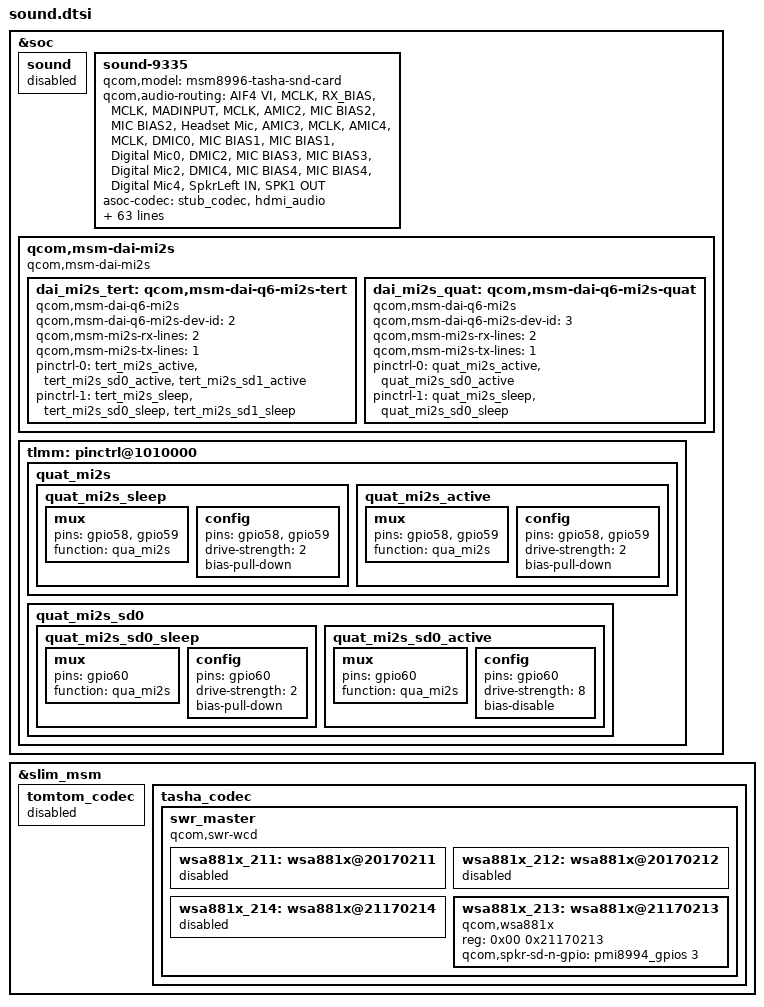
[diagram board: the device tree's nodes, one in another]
/* Copyright (c) 2015, The Linux Foundation. All rights reserved.
 *
 * This program is free software; you can redistribute it and/or modify
 * it under the terms of the GNU General Public License version 2 and
 * only version 2 as published by the Free Software Foundation.
 *
 * This program is distributed in the hope that it will be useful,
 * but WITHOUT ANY WARRANTY; without even the implied warranty of
 * MERCHANTABILITY or FITNESS FOR A PARTICULAR PURPOSE.  See the
 * GNU General Public License for more details.
 */


&soc {

	sound {
		status = "disabled";
	};

	sound-9335 {
		qcom,model = "msm8996-tasha-snd-card";

		qcom,audio-routing =
			"AIF4 VI", "MCLK",
			"RX_BIAS", "MCLK",
			"MADINPUT", "MCLK",
			"AMIC2", "MIC BIAS2",
			"MIC BIAS2", "Headset Mic",
			"AMIC3", "MCLK",
			"AMIC4", "MCLK",
			"DMIC0", "MIC BIAS1",
			"MIC BIAS1", "Digital Mic0",
			"DMIC2", "MIC BIAS3",
			"MIC BIAS3", "Digital Mic2",
			"DMIC4", "MIC BIAS4",
			"MIC BIAS4", "Digital Mic4",
			"SpkrLeft IN", "SPK1 OUT";

		asoc-codec = <&stub_codec>, <&hdmi_audio>;
		asoc-codec-names = "msm-stub-codec.1", "msm-hdmi-audio-codec-rx";
		asoc-cpu = <&dai_pri_auxpcm>, <&dai_sec_auxpcm>, <&dai_hdmi>, <&dai_mi2s_sec>, <&dai_mi2s_tert>,<&dai_mi2s_quat>,
			<&sb_0_rx>, <&sb_0_tx>, <&sb_1_rx>, <&sb_1_tx>,
			<&sb_2_rx>, <&sb_2_tx>, <&sb_3_rx>, <&sb_3_tx>,
			<&sb_4_rx>, <&sb_4_tx>, <&sb_5_tx>, <&afe_pcm_rx>,
			<&afe_pcm_tx>, <&afe_proxy_rx>, <&afe_proxy_tx>,
			<&incall_record_rx>, <&incall_record_tx>,
			<&incall_music_rx>, <&incall_music2_rx>,
			<&sb_5_rx>, <&sb_6_rx>,
			<&usb_audio_rx>, <&usb_audio_tx>,
			<&dai_pri_tdm_tx_0>, <&dai_pri_tdm_tx_1>,
			<&dai_pri_tdm_tx_2>, <&dai_pri_tdm_tx_3>,
			<&dai_pri_tdm_rx_0>, <&dai_pri_tdm_rx_1>,
			<&dai_pri_tdm_rx_2>, <&dai_pri_tdm_rx_3>,
			<&dai_sec_tdm_rx_0>, <&dai_sec_tdm_rx_1>,
			<&dai_sec_tdm_rx_2>, <&dai_sec_tdm_rx_3>,
			<&dai_sec_tdm_tx_0>, <&dai_sec_tdm_tx_1>,
			<&dai_sec_tdm_tx_2>, <&dai_sec_tdm_tx_3>,
			<&dai_tert_tdm_rx_0>, <&dai_tert_tdm_rx_1>,
			<&dai_tert_tdm_rx_2>, <&dai_tert_tdm_rx_3>,
			<&dai_tert_tdm_tx_0>, <&dai_tert_tdm_tx_1>,
			<&dai_tert_tdm_tx_2>, <&dai_tert_tdm_tx_3>,
			<&dai_quat_tdm_rx_0>, <&dai_quat_tdm_rx_1>,
			<&dai_quat_tdm_rx_2>, <&dai_quat_tdm_rx_3>,
			<&dai_quat_tdm_tx_0>, <&dai_quat_tdm_tx_1>,
			<&dai_quat_tdm_tx_2>, <&dai_quat_tdm_tx_3>;
		asoc-cpu-names = "msm-dai-q6-auxpcm.1", "msm-dai-q6-auxpcm.2",
			"msm-dai-q6-hdmi.8", "msm-dai-q6-mi2s.1","msm-dai-q6-mi2s.2","msm-dai-q6-mi2s.3",
			"msm-dai-q6-dev.16384", "msm-dai-q6-dev.16385",
			"msm-dai-q6-dev.16386", "msm-dai-q6-dev.16387",
			"msm-dai-q6-dev.16388", "msm-dai-q6-dev.16389",
			"msm-dai-q6-dev.16390", "msm-dai-q6-dev.16391",
			"msm-dai-q6-dev.16392", "msm-dai-q6-dev.16393",
			"msm-dai-q6-dev.16395",
			"msm-dai-q6-dev.224", "msm-dai-q6-dev.225",
			"msm-dai-q6-dev.241", "msm-dai-q6-dev.240",
			"msm-dai-q6-dev.32771", "msm-dai-q6-dev.32772",
			"msm-dai-q6-dev.32773", "msm-dai-q6-dev.32770",
			"msm-dai-q6-dev.16394", "msm-dai-q6-dev.16396",
			"msm-dai-q6-dev.28672", "msm-dai-q6-dev.28673",
			"msm-dai-q6-tdm.36865", "msm-dai-q6-tdm.36867",
			"msm-dai-q6-tdm.36869", "msm-dai-q6-tdm.36871",
			"msm-dai-q6-tdm.36864", "msm-dai-q6-tdm.36866",
			"msm-dai-q6-tdm.36868", "msm-dai-q6-tdm.36870",
			"msm-dai-q6-tdm.36880", "msm-dai-q6-tdm.36882",
			"msm-dai-q6-tdm.36884", "msm-dai-q6-tdm.36886",
			"msm-dai-q6-tdm.36881", "msm-dai-q6-tdm.36883",
			"msm-dai-q6-tdm.36885", "msm-dai-q6-tdm.36887",
			"msm-dai-q6-tdm.36896", "msm-dai-q6-tdm.36898",
			"msm-dai-q6-tdm.36900", "msm-dai-q6-tdm.36902",
			"msm-dai-q6-tdm.36897", "msm-dai-q6-tdm.36899",
			"msm-dai-q6-tdm.36901", "msm-dai-q6-tdm.36903",
			"msm-dai-q6-tdm.36912", "msm-dai-q6-tdm.36914",
			"msm-dai-q6-tdm.36916", "msm-dai-q6-tdm.36918",
			"msm-dai-q6-tdm.36913", "msm-dai-q6-tdm.36915",
			"msm-dai-q6-tdm.36917", "msm-dai-q6-tdm.36919";
		qcom,wsa-max-devs = <1>;
		qcom,wsa-devs = <&wsa881x_213>;
		qcom,wsa-aux-dev-prefix = "SpkrLeft";
		qcom,msm-mbhc-hphl-swh = <1>;
		qcom,mbhc-audio-jack-type = "4-pole-jack";
	};

	qcom,msm-dai-mi2s {
		compatible = "qcom,msm-dai-mi2s";
		dai_mi2s_tert: qcom,msm-dai-q6-mi2s-tert {
			compatible = "qcom,msm-dai-q6-mi2s";
			qcom,msm-dai-q6-mi2s-dev-id = <2>;
			qcom,msm-mi2s-rx-lines = <2>;
			qcom,msm-mi2s-tx-lines = <1>;
			pinctrl-names = "default", "idle";
			pinctrl-0 = <&tert_mi2s_active &tert_mi2s_sd0_active &tert_mi2s_sd1_active>;
			pinctrl-1 = <&tert_mi2s_sleep &tert_mi2s_sd0_sleep &tert_mi2s_sd1_sleep>;
		};

        dai_mi2s_quat: qcom,msm-dai-q6-mi2s-quat {
			compatible = "qcom,msm-dai-q6-mi2s";
			qcom,msm-dai-q6-mi2s-dev-id = <3>;
			qcom,msm-mi2s-rx-lines = <2>; /* SD0 (1 << 0) | SD1 (1 << 1) | SD2 (1 << 2) */
			qcom,msm-mi2s-tx-lines = <1>; /* SD2 (1 << 3) */
			pinctrl-names = "default", "sleep";
			pinctrl-0 = <&quat_mi2s_active &quat_mi2s_sd0_active>;
			pinctrl-1 = <&quat_mi2s_sleep &quat_mi2s_sd0_sleep>;
		};
	};

	tlmm: pinctrl@1010000 {
			quat_mi2s {
				quat_mi2s_sleep: quat_mi2s_sleep {
					mux {
						pins = "gpio58", "gpio59";
						function = "qua_mi2s";
					};

					config {
						pins = "gpio58", "gpio59";
						drive-strength = <2>;   /* 2 mA */
						bias-pull-down;         /* PULL DOWN */
					};
				};
				quat_mi2s_active: quat_mi2s_active {
					mux {
						pins = "gpio58", "gpio59";
						function = "qua_mi2s";
					};

					config {
						pins = "gpio58", "gpio59";
						drive-strength = <2>;
						bias-pull-down;
					};
				};
			};

			quat_mi2s_sd0 {
				quat_mi2s_sd0_sleep: quat_mi2s_sd0_sleep {
					mux {
						pins = "gpio60";
						function = "qua_mi2s";
					};

					config {
						pins = "gpio60";
						drive-strength = <2>;   /* 2 mA */
						bias-pull-down;         /* PULL DOWN */
					};
				};
				quat_mi2s_sd0_active: quat_mi2s_sd0_active {
					mux {
						pins = "gpio60";
						function = "qua_mi2s";
					};

					config {
						pins = "gpio60";
						drive-strength = <8>;   /* 8 mA */
						bias-disable;           /* NO PULL */
					};
				};
			};
	};

};

&slim_msm {
	tomtom_codec {
		status = "disabled";
	};
	tasha_codec {
		swr_master {
			compatible = "qcom,swr-wcd";
			#address-cells = <2>;
			#size-cells = <0>;

			wsa881x_211: wsa881x@20170211 {
				status = "disabled";
			};
			wsa881x_212: wsa881x@20170212 {
				status = "disabled";
			};
			wsa881x_214: wsa881x@21170214 {
				status = "disabled";
			};

			wsa881x_213: wsa881x@21170213 {
				compatible = "qcom,wsa881x";
				reg = <0x00 0x21170213>;
				qcom,spkr-sd-n-gpio = <&pmi8994_gpios 3 0>;
			};
		};
	};
};
